AUTOSAR XML (schema 4-2-1)
package /RootP_SR_Data
  sender receiver interface SR_ApportCarbDetecteTest
    data ApportCarbDetecteTest: type=tLOG, init-value=CONST_tLOG_0:0
  sender receiver interface SR_TrebuieSaApara
    data ApportCarbDetecte: type=tLOG, init-value=CONST_tLOG_0:0
package /RootP_ASWC_A26
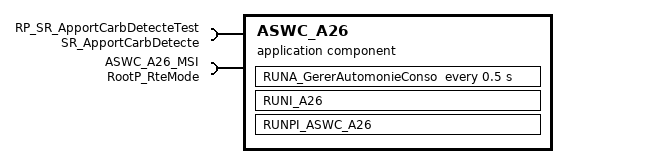
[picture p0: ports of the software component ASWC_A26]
  application sw component type ASWC_A26
    37 x provide/require port:
      PRP_SR_Autonomie: nonqueued-receiver-com-spec{data-element=Autonomie, enable-update=0, handle-data-status=1, handle-never-received=0, init-value=CONST_Autonomie_tWORD_0xFFFF:0xFFFF}, provided-required-interface=SR_Autonomie
      PRP_SR_AutonomieGPL: nonqueued-receiver-com-spec{data-element=AutonomieGPL, enable-update=0, handle-data-status=1, handle-never-received=0, init-value=CONST_AutonomieGPL_tWORD_0x7FF:0x7FF}, provided-required-interface=SR_AutonomieGPL
      PRP_SR_AutonomieInvalide: nonqueued-receiver-com-spec{data-element=AutonomieInvalide, enable-update=0, handle-data-status=1, handle-never-received=0, init-value=CONST_AutonomieInvalide_tLOG_0:0}, provided-required-interface=SR_AutonomieInvalide
      PRP_SR_AutonomieTOTAL: nonqueued-receiver-com-spec{data-element=AutonomieTOTAL, enable-update=0, handle-data-status=1, handle-never-received=0, init-value=CONST_AutonomieTOTAL_tWORD_0x7FF:0x7FF}, provided-required-interface=SR_AutonomieTOTAL
      PRP_SR_ConsoAutonomieGM: nonqueued-receiver-com-spec{data-element=ConsoAutonomieGM, enable-update=0, handle-data-status=1, handle-never-received=0, init-value=CONST_ConsoAutonomieGM_tDWORD_0:0}, provided-required-interface=SR_ConsoAutonomieGM
      PRP_SR_ConsoGPLInvalide: nonqueued-receiver-com-spec{data-element=ConsoGPLInvalide, enable-update=0, handle-data-status=1, handle-never-received=0, init-value=CONST_ConsoGPLInvalide_tLOG_0:0}, provided-required-interface=SR_ConsoGPLInvalide
      PRP_SR_ConsoInst: nonqueued-receiver-com-spec{data-element=ConsoInst, enable-update=0, handle-data-status=1, handle-never-received=0, init-value=CONST_ConsoInst_tWORD_0xFFFF:0xFFFF}, provided-required-interface=SR_ConsoInst
      PRP_SR_ConsoInstGPL: nonqueued-receiver-com-spec{data-element=ConsoInstGPL, enable-update=0, handle-data-status=1, handle-never-received=0, init-value=CONST_ConsoInstGPL_tWORD_0x1FF:0x1FF}, provided-required-interface=SR_ConsoInstGPL
      PRP_SR_ConsoLissee: nonqueued-receiver-com-spec{data-element=ConsoLissee, enable-update=0, handle-data-status=1, handle-never-received=0, init-value=CONST_ConsoLissee_tWORD_0:0}, provided-required-interface=SR_ConsoLissee
      PRP_SR_ConsoMoyenneGPLT1: nonqueued-receiver-com-spec{data-element=ConsoMoyenneGPLT1, enable-update=0, handle-data-status=1, handle-never-received=0, init-value=CONST_ConsoMoyenneGPLT1_tWORD_0:0}, provided-required-interface=SR_ConsoMoyenneGPLT1
      PRP_SR_ConsoMoyenneGPLT2: nonqueued-receiver-com-spec{data-element=ConsoMoyenneGPLT2, enable-update=0, handle-data-status=1, handle-never-received=0, init-value=CONST_ConsoMoyenneGPLT2_tWORD_0:0}, provided-required-interface=SR_ConsoMoyenneGPLT2
      PRP_SR_ConsoMoyenneHY{1..6}: nonqueued-receiver-com-spec{data-element=ConsoMoyenneHY{1..6}, enable-update=0, handle-data-status=1, handle-never-received=0, init-value=CONST_ConsoMoyenneHY{1..6}_tBYTE_0:0}, provided-required-interface=SR_ConsoMoyenneHY{1..6}
      PRP_SR_ConsoMoyenneT1: nonqueued-receiver-com-spec{data-element=ConsoMoyenneT1, enable-update=0, handle-data-status=1, handle-never-received=0, init-value=CONST_ConsoMoyenneT1_tWORD_0:0}, provided-required-interface=SR_ConsoMoyenneT1
      PRP_SR_ConsoMoyenneT2: nonqueued-receiver-com-spec{data-element=ConsoMoyenneT2, enable-update=0, handle-data-status=1, handle-never-received=0, init-value=CONST_ConsoMoyenneT2_tWORD_0:0}, provided-required-interface=SR_ConsoMoyenneT2
      PRP_SR_ConsoReelleInvalide: nonqueued-receiver-com-spec{data-element=ConsoReelleInvalide, enable-update=0, handle-data-status=1, handle-never-received=0, init-value=CONST_ConsoReelleInvalide_tLOG_0:0}, provided-required-interface=SR_ConsoReelleInvalide
      PRP_SR_Conso_WH_Gain{1..6}: nonqueued-receiver-com-spec{data-element=Conso_WH_Gain{1..6}, enable-update=0, handle-data-status=1, handle-never-received=0, init-value=CONST_Conso_WH_Gain{1..6}_tBYTE_0:0}, provided-required-interface=SR_Conso_WH_Gain{1..6}
      PRP_SR_DistAutonomieGM: nonqueued-receiver-com-spec{data-element=DistAutonomieGM, enable-update=0, handle-data-status=1, handle-never-received=0, init-value=CONST_DistAutonomieGM_tDWORD_0:0}, provided-required-interface=SR_DistAutonomieGM
      PRP_SR_NbDemiMedaillesBarre{1..6}: nonqueued-receiver-com-spec{data-element=NbDemiMedaillesBarre{1..6}, enable-update=0, handle-data-status=1, handle-never-received=0, init-value=CONST_NbDemiMedaillesBarre{1..6}_tWORD_0:0}, provided-required-interface=SR_NbDemiMedaillesBarre{1..6}
      PRP_SR_PseudoConsoInvalide: nonqueued-receiver-com-spec{data-element=PseudoConsoInvalide, enable-update=0, handle-data-status=1, handle-never-received=0, init-value=CONST_PseudoConsoInvalide_tLOG_0:0}, provided-required-interface=SR_PseudoConsoInvalide
      PRP_SR_RazOkDeAuCoVersOdo: nonqueued-receiver-com-spec{data-element=RazOkDeAuCoVersOdo, enable-update=0, handle-data-status=1, handle-never-received=0, init-value=CONST_RazOkDeAuCoVersOdo_tLOG_0:0}, provided-required-interface=SR_RazOkDeAuCoVersOdo
      PRP_SR_SAV_ConsoGPLLisse: nonqueued-receiver-com-spec{data-element=SAV_ConsoGPLLisse, enable-update=0, handle-data-status=1, handle-never-received=0, init-value=CONST_SAV_ConsoGPLLisse_tWORD_100:100}, provided-required-interface=SR_SAV_ConsoGPLLisse
      PRP_SR_SAV_ConsoLisse: nonqueued-receiver-com-spec{data-element=SAV_ConsoLisse, enable-update=0, handle-data-status=1, handle-never-received=0, init-value=CONST_SAV_ConsoLisse_tWORD_100:100}, provided-required-interface=SR_SAV_ConsoLisse
    require port RP_SR_ApportCarbDetecteTest: nonqueued-receiver-com-spec{data-element=ApportCarbDetecteTest, enable-update=0, handle-data-status=1, handle-never-received=0, init-value=CONST_ApportCarbDetecte_tLOG_0:0}, required-interface=SR_ApportCarbDetecte
    require port ASWC_A26_MSI: required-interface=RootP_RteMode
    behavior IB_ASWC_A26: data-type-mapping=ApplicationModeMapping, handle-termination-and-restart=NO-SUPPORT
      ar-typed-per-instance-memorys:
        155 x data:
          PA26_ApportCarbDetecte_prec: type=tLOG, init-value=CONST_tLOG_0:0
          PA26_AutonomieCorrigee: type=tWORD, init-value=CONST_tWORD_0:0
          PA26_AutonomieCorrigeeGPL: type=tWORD, init-value=CONST_tWORD_0:0
          PA26_AutonomieHyst: type=tWORD, init-value=CONST_tWORD_0xFFFF:0xFFFF
          PA26_AutonomieHystGPL: type=tWORD, init-value=CONST_tWORD_0xFFFF:0xFFFF
          PA26_AutonomieNonCorrigee: type=tWORD, init-value=CONST_tWORD_0:0
          PA26_AutonomieNonCorrigeeGPL: type=tWORD, init-value=CONST_tWORD_0:0
          PA26_CalculAutonomie: type=tLOG, init-value=CONST_tLOG_0:0
          PA26_CalculAutonomieGPL_GM: type=tLOG, init-value=CONST_tLOG_0:0
          PA26_CalculAutonomieGPL_PSA: type=tLOG, init-value=CONST_tLOG_0:0
          PA26_CalculConso: type=tWORD, init-value=CONST_tWORD_0:0
          PA26_CalculConsoInst: type=tLOG, init-value=CONST_tLOG_0:0
          PA26_CalculConsoInstGPL: type=tLOG, init-value=CONST_tLOG_0:0
          PA26_ConsoCarbReellePrec: type=tBYTE, init-value=CONST_tBYTE_0:0
          PA26_ConsoInst: type=tWORD, init-value=CONST_tWORD_100:100
          PA26_ConsoInstantanee: type=tWORD, init-value=CONST_tWORD_100:100
          PA26_ConsoInstantaneeGPL: type=tWORD, init-value=CONST_tWORD_100:100
          PA26_ConsoInstantGPLPrec: type=tWORD, init-value=CONST_tWORD_100:100
          PA26_ConsoInstantPrec: type=tWORD, init-value=CONST_tWORD_100:100
          PA26_ConsoInstGPL: type=tWORD, init-value=CONST_tWORD_100:100
          PA26_ConsoInstGPLPrec: type=tWORD, init-value=CONST_tWORD_0:0
          PA26_ConsoInstPrec: type=tWORD, init-value=CONST_tWORD_0:0
          PA26_ConsommationGPLPrec: type=tBYTE, init-value=CONST_tBYTE_0:0
          PA26_ConsoMoyenneHY: type=tWORD, init-value=CONST_tWORD_0:0
          PA26_ConsoMoyenneT1GPL: type=tWORD, init-value=CONST_tWORD_0:0
          PA26_ConsoMoyenneT2GPL: type=tWORD, init-value=CONST_tWORD_0:0
          PA26_ConsoMoyenneZoom1Barre{1..6}: type=tBYTE, init-value=CONST_tBYTE_0:0
          PA26_ConsoMoyenneZoom2Barre{1..6}: type=tBYTE, init-value=CONST_tBYTE_0:0
          PA26_ConsoMoyenneZoom3Barre{1..6}: type=tBYTE, init-value=CONST_tBYTE_0:0
          PA26_ConsoMoyenneZoom4Barre{1..6}: type=tBYTE, init-value=CONST_tBYTE_0:0
          PA26_DdeRazOdoPrec: type=tLOG, init-value=CONST_tLOG_0:0
          PA26_DeltaConso: type=tBYTE, init-value=CONST_tBYTE_0:0
          PA26_DeltaConsoGPL: type=tBYTE, init-value=CONST_tBYTE_0:0
          PA26_DeltaConsoReelle: type=tBYTE, init-value=CONST_tBYTE_0:0
          PA26_DeltaDistance: type=tWORD, init-value=CONST_tWORD_0:0
          PA26_DeltaDistanceParcourue: type=tWORD, init-value=CONST_tWORD_0:0
          PA26_DeltaPseudoConsommationCarb: type=tBYTE, init-value=CONST_tBYTE_0:0
          PA26_DistanceParcourue_Prec: type=tWORD, init-value=CONST_tWORD_0:0
          PA26_DistancePreciseT1Prec: type=tDWORD, init-value=CONST_tDWORD_0:0
          PA26_DistancePreciseT2Prec: type=tDWORD, init-value=CONST_tDWORD_0:0
          PA26_DistParcourueHy: type=tDWORD, init-value=CONST_tDWORD_0:0
          PA26_DistParcourueHy_memo: type=tDWORD, init-value=CONST_tDWORD_0:0
          PA26_DistParcourueHy_temp: type=tDWORD, init-value=CONST_tDWORD_0:0
          PA26_DistParcourueZoom1: type=tDWORD, init-value=CONST_tDWORD_0:0
          PA26_DistParcourueZoom1_memo: type=tDWORD, init-value=CONST_tDWORD_0:0
          PA26_DistParcourueZoom1_Prec: type=tDWORD, init-value=CONST_tDWORD_0:0
          PA26_DistParcourueZoom1_temp: type=tDWORD, init-value=CONST_tDWORD_0:0
          PA26_DistParcourueZoom2: type=tDWORD, init-value=CONST_tDWORD_0:0
          PA26_DistParcourueZoom2_memo: type=tDWORD, init-value=CONST_tDWORD_0:0
          PA26_DistParcourueZoom2_Prec: type=tDWORD, init-value=CONST_tDWORD_0:0
          PA26_DistParcourueZoom2_temp: type=tDWORD, init-value=CONST_tDWORD_0:0
          PA26_DistParcourueZoom3: type=tDWORD, init-value=CONST_tDWORD_0:0
          PA26_DistParcourueZoom3_memo: type=tDWORD, init-value=CONST_tDWORD_0:0
          PA26_DistParcourueZoom3_Prec: type=tDWORD, init-value=CONST_tDWORD_0:0
          PA26_DistParcourueZoom3_temp: type=tDWORD, init-value=CONST_tDWORD_0:0
          PA26_DistParcourueZoom4: type=tDWORD, init-value=CONST_tDWORD_0:0
          PA26_DistParcourueZoom4_memo: type=tDWORD, init-value=CONST_tDWORD_0:0
          PA26_DistParcourueZoom4_Prec: type=tDWORD, init-value=CONST_tDWORD_0:0
          PA26_DistParcourueZoom4_temp: type=tDWORD, init-value=CONST_tDWORD_0:0
          PA26_EnergieCalcule: type=tBinaire, init-value=CONST_PA26_EnergieCalcule_tBinaire_cFaux:0
          PA26_EtatConsoMoyenneHY_Valide: type=tBinaire, init-value=CONST_PA26_EtatConsoMoyenneHY_Valide_tBinaire_cVrai:1
          PA26_EtatConsoMoyenneZoom{1..4}_Valide: type=tBinaire, init-value=CONST_PA26_EtatConsoMoyenneZoom{1..4}_Valide_tBinaire_cVrai:1
          PA26_EtatDefautConsoGPL: type=tBYTE, init-value=CONST_tBYTE_15:15
          PA26_EtatDefautConsoReelle: type=tBYTE, init-value=CONST_tBYTE_15:15
          PA26_EtatDefautPseudoConso: type=tBYTE, init-value=CONST_tBYTE_15:15
          PA26_EtatFiltreODBConsoGPLLisse: type=tDWORD, init-value=CONST_tDWORD_0x00032000:0x00032000
          PA26_EtatFiltreODBConsoInst: type=tDWORD, init-value=CONST_tDWORD_1000:1000
          PA26_EtatFiltreODBConsoInstGPL: type=tDWORD, init-value=CONST_tDWORD_1000:1000
          PA26_EtatFiltreODBConsoLisse: type=tDWORD, init-value=CONST_tDWORD_0x00032000:0x00032000
          PA26_EtatFiltreODBMoyenneConso: type=tDWORD, init-value=CONST_tDWORD_0xFFFFFFFF:0xFFFFFFFF
          PA26_EtatFiltreODBMoyenneConsoGPL: type=tDWORD, init-value=CONST_tDWORD_0xFFFFFFFF:0xFFFFFFFF
          PA26_EtatGMPDeHY_Prec: type=t_cEtatHY, init-value=CONST_PA26_EtatGMPDeHY_Prec_t_cEtatHY_cEtatHY_Indetermine:0
          PA26_EtatGMPHy_Valide: type=t_cEtatHY, init-value=CONST_PA26_EtatGMPHy_Valide_t_cEtatHY_cEtatHY_Indetermine:0
          PA26_EtatSurvAcqConso: type=tBILOG, init-value=CONST_tBILOG_0:0
          PA26_FlagAffichageAutonomieInv: type=tLOG, init-value=CONST_tLOG_0:0
          PA26_FlagAffichageAutonomieInvGPL: type=tLOG, init-value=CONST_tLOG_0:0
          PA26_FlagCalculAutonomieInv: type=tLOG, init-value=CONST_tLOG_0:0
          PA26_FlagModeDeFonction: type=tLOG, init-value=CONST_tLOG_0:0
          PA26_Mode_GAZ_Essence: type=tBILOG, init-value=CONST_tBILOG_0:0
          PA26_Mode_GAZ_Essence_Prec: type=tBILOG, init-value=CONST_tBILOG_0:0
          PA26_MoyenneGPLConso: type=tWORD, init-value=CONST_tWORD_100:100
          PA26_NivCarbAffVersCmb: type=tBYTE, init-value=CONST_tBYTE_0:0
          PA26_NivGPLAffichefiltre: type=tBYTE, init-value=CONST_tBYTE_0:0
          PA26_NivGPLAffiche_prec: type=tBYTE, init-value=CONST_tBYTE_0:0
          PA26_OldCstTpsConsoInst: type=tWORD, init-value=CONST_tWORD_10:10
          PA26_OldCstTpsConsoInstGPL: type=tWORD, init-value=CONST_tWORD_10:10
          PA26_OldCstTpsConsoLissee: type=tWORD, init-value=CONST_tWORD_4000:4000
          PA26_PasAffAutonomie: type=tBYTE, init-value=CONST_tBYTE_0:0
          PA26_PasAffAutonomieGPL: type=tBYTE, init-value=CONST_tBYTE_0:0
          PA26_PasAutonomie: type=tBYTE, init-value=CONST_tBYTE_0:0
          PA26_PasAutonomieGPL: type=tBYTE, init-value=CONST_tBYTE_0:0
          PA26_PseudoConsommationCarb_Prec: type=tBYTE, init-value=CONST_tBYTE_0:0
          PA26_QteCarbConsoHy: type=tDWORD, init-value=CONST_tDWORD_0:0
          PA26_QteCarbConsoZoom{1..4}: type=tDWORD, init-value=CONST_tDWORD_0:0
          PA26_QteEnergieRecup: type=tBYTE, init-value=CONST_tBYTE_0:0
          PA26_QteEnergieRecup_memo: type=tBYTE, init-value=CONST_tBYTE_0:0
          PA26_QteEnergieRecup_Prec: type=tBYTE, init-value=CONST_tBYTE_0:0
          PA26_QteEnergieRecup_temp: type=tBYTE, init-value=CONST_tBYTE_0:0
          PA26_SAV_ConsoPreciseT1GPL: type=tDWORD, init-value=CONST_tDWORD_0:0
          PA26_SAV_ConsoPreciseT2GPL: type=tDWORD, init-value=CONST_tDWORD_0:0
          PA26_SAV_DeltaDistancePreciseT1Gaz: type=tDWORD, init-value=CONST_tDWORD_0:0
          PA26_SAV_DeltaDistancePreciseT1GazMem: type=tDWORD, init-value=CONST_tDWORD_0:0
          PA26_SAV_DeltaDistancePreciseT2Gaz: type=tDWORD, init-value=CONST_tDWORD_0:0
          PA26_SAV_DeltaDistancePreciseT2GazMem: type=tDWORD, init-value=CONST_tDWORD_0:0
          PA26_SAV_DistancePreciseT1Prec: type=tDWORD, init-value=CONST_tDWORD_0:0
          PA26_SAV_DistancePreciseT2Prec: type=tDWORD, init-value=CONST_tDWORD_0:0
          PA26_SAV_DistanceT1EssGazMem: type=tDWORD, init-value=CONST_tDWORD_0:0
          PA26_SAV_DistanceT1HorsGaz: type=tDWORD, init-value=CONST_tDWORD_0:0
          PA26_SAV_DistanceT2EssGazMem: type=tDWORD, init-value=CONST_tDWORD_0:0
          PA26_SAV_DistanceT2HorsGaz: type=tDWORD, init-value=CONST_tDWORD_0:0
          PA26_SEC_PremierTelechBSI: type=tLOG, init-value=CONST_tLOG_0:0
          PA26_TempoConfirmDefaut: type=tBYTE, init-value=CONST_tBYTE_0:0
          PA26_TempoDefautConsoGPL: type=tWORD, init-value=CONST_tWORD_0:0
          PA26_TempoDefautConsoReelle: type=tWORD, init-value=CONST_tWORD_0:0
          PA26_TempoDefautPseudoConso: type=tWORD, init-value=CONST_tWORD_0:0
          PA26_TempoGM: type=tBYTE, init-value=CONST_tBYTE_0:0
          PA26_TempoHy: type=tWORD, init-value=CONST_tWORD_0:0
          PA26_TempoMaJ1Seconde: type=tBYTE, init-value=CONST_tBYTE_0:0
          PA26_TempoMaJ1SecondeGPL: type=tBYTE, init-value=CONST_tBYTE_0:0
          PA26_TempoMaJ2Seconde: type=tBYTE, init-value=CONST_tBYTE_0:0
          PA26_TempoMaJ2SecondeGPL: type=tBYTE, init-value=CONST_tBYTE_0:0
          PA26_TempoZoom{1..4}: type=tBYTE, init-value=CONST_tBYTE_0:0
          PA26_Toggle_ConsoLissee: type=tLOG, init-value=CONST_tLOG_0:0
          PA26_Toggle_ConsoLisseeGPL: type=tLOG, init-value=CONST_tLOG_0:0
          PA26_Toggle_ConsoMoyenne: type=tLOG, init-value=CONST_tLOG_0:0
          PA26_Toggle_ConsoMoyenneGPL: type=tLOG, init-value=CONST_tLOG_0:0
      timing event RUNA_GererAutomonieConso_Cyclic: start-on-event=RUNA_GererAutomonieConso, period=0.5
        disabled-mode:
          ASWC_A26_MSI.RteMode.APP_WAKEUP
          ASWC_A26_MSI.RteMode.APP_OFF
          ASWC_A26_MSI.RteMode.APP_SYNC_INIT
          ASWC_A26_MSI.RteMode.APP_CONFIG
      swc mode switch event RUNPI_ASWC_A26_ENTRY: start-on-event=RUNPI_ASWC_A26, activation=ON-ENTRY, mode=ASWC_A26_MSI.RteMode.APP_WAKEUP
      swc mode switch event RUNI_A26_EXIT: start-on-event=RUNI_A26, activation=ON-EXIT, mode=ASWC_A26_MSI.RteMode.APP_WAKEUP
      implicit-inter-runnable-variables:
        5 x data:
          IRVA26_ConsoMoyT1: type=tWORD, init-value=CONST_tWORD_0:0
          IRVA26_ConsoMoyT2: type=tWORD, init-value=CONST_tWORD_0:0
          IRVA26_ConsoPreciseT1: type=tDWORD, init-value=CONST_tDWORD_0:0
          IRVA26_ConsoPreciseT2: type=tDWORD, init-value=CONST_tDWORD_0:0
          IRVA26_MoyenneConso: type=tWORD, init-value=CONST_tWORD_70:70
      runnable RUNA_GererAutomonieConso
        data-read-access:
          162 x access:
            dra_ApportCarbDetecte: accessed-variable=RP_SR_ApportCarbDetecte.ApportCarbDetecte
            dra_CMMMuet_P26: accessed-variable=RP_SR_CMMMuet_P26.CMMMuet_P26
            dra_ConsommationCarbReelle_P26: accessed-variable=RP_SR_ConsommationCarbReelle_P26.ConsommationCarbReelle_P26
            dra_ConsommationGPL: accessed-variable=RP_SR_ConsommationGPL.ConsommationGPL
            dra_DdeRazDeOdometre: accessed-variable=RP_SR_DdeRazDeOdometre.DdeRazDeOdometre
            dra_DdeRazT1_P26: accessed-variable=RP_SR_DdeRazT1_P26.DdeRazT1_P26
            dra_DdeRazT2_P26: accessed-variable=RP_SR_DdeRazT2_P26.DdeRazT2_P26
            dra_DefautJaugeCarbConfirme: accessed-variable=RP_SR_DefautJaugeCarbConfirme.DefautJaugeCarbConfirme
            dra_DistanceParcourue: accessed-variable=RP_SR_DistanceParcourue.DistanceParcourue
            dra_DistanceParcourueFigee: accessed-variable=RP_SR_DistanceParcourueFigee.DistanceParcourueFigee
            dra_DistanceParcourueValide: accessed-variable=RP_SR_DistanceParcourueValide.DistanceParcourueValide
            dra_DistanceT1: accessed-variable=RP_SR_DistanceT1.DistanceT1
            dra_DistanceT2: accessed-variable=RP_SR_DistanceT2.DistanceT2
            dra_DysfVitesseVehicule: accessed-variable=RP_SR_DysfVitesseVehicule.DysfVitesseVehicule
            dra_EtatGMP: accessed-variable=RP_SR_EtatGMP.EtatGMP
            dra_EtatGMPDeHY: accessed-variable=RP_SR_EtatGMPDeHY.EtatGMPDeHY
            dra_EtatModeGaz: accessed-variable=RP_SR_EtatModeGaz.EtatModeGaz
            dra_EtatPrincipalSEV: accessed-variable=RP_SR_EtatPrincipalSEV.EtatPrincipalSEV
            dra_GAZMuet_P26: accessed-variable=RP_SR_GAZMuet_P26.GAZMuet_P26
            dra_GPLModeINFO: accessed-variable=RP_SR_GPLModeINFO.GPLModeINFO
            dra_GPLtankCapacity: accessed-variable=RP_SR_GPLtankCapacity.GPLtankCapacity
            dra_ModeFonctMotGAZ: accessed-variable=RP_SR_ModeFonctMotGAZ.ModeFonctMotGAZ
            dra_NivGPLAffiche: accessed-variable=RP_SR_NivGPLAffiche.NivGPLAffiche
            dra_PhaseVieLS: accessed-variable=RP_SR_PhaseVieLS.PhaseVieLS
            dra_PremiereMesureJC_OK: accessed-variable=RP_SR_PremiereMesureJC_OK.PremiereMesureJC_OK
            dra_PseudoConsommationCarb: accessed-variable=RP_SR_PseudoConsommationCarb.PseudoConsommationCarb
            dra_QteEnergieRecup: accessed-variable=RP_SR_QteEnergieRecup.QteEnergieRecup
            dra_RegimeMoteur_P26: accessed-variable=RP_SR_RegimeMoteur_P26.RegimeMoteur_P26
            dra_SAV_DistancePreciseT1: accessed-variable=RP_SR_SAV_DistancePreciseT1.SAV_DistancePreciseT1
            dra_SAV_DistancePreciseT2: accessed-variable=RP_SR_SAV_DistancePreciseT2.SAV_DistancePreciseT2
            dra_SAV_EtatReseauElectrique: accessed-variable=RP_SR_SAV_EtatReseauElectrique.SAV_EtatReseauElectrique
            dra_SAV_NivCarbAffiche: accessed-variable=RP_SR_SAV_NivCarbAffiche.SAV_NivCarbAffiche
            dra_VitesseVehicule: accessed-variable=RP_SR_VitesseVehicule.VitesseVehicule
            dra_ZoomConsoIHM: accessed-variable=RP_SR_ZoomConsoIHM.ZoomConsoIHM
            dra_C_CONSO_AUTONOMIE_MAX: accessed-variable=RP_SR_C_CONSO_AUTONOMIE_MAX.C_CONSO_AUTONOMIE_MAX
            dra_C_CONSO_BORNE_AUTONOMIE_1: accessed-variable=RP_SR_C_CONSO_BORNE_AUTONOMIE_1.C_CONSO_BORNE_AUTONOMIE_1
            dra_C_CONSO_BORNE_AUTONOMIE_2: accessed-variable=RP_SR_C_CONSO_BORNE_AUTONOMIE_2.C_CONSO_BORNE_AUTONOMIE_2
            dra_C_CONSO_COEF_HYST_MOINS: accessed-variable=RP_SR_C_CONSO_COEF_HYST_MOINS.C_CONSO_COEF_HYST_MOINS
            dra_C_CONSO_COEF_HYST_PLUS: accessed-variable=RP_SR_C_CONSO_COEF_HYST_PLUS.C_CONSO_COEF_HYST_PLUS
            dra_C_CONSO_DISTANCE_MAX: accessed-variable=RP_SR_C_CONSO_DISTANCE_MAX.C_CONSO_DISTANCE_MAX
            dra_C_CONSO_DISTANCE_MINI: accessed-variable=RP_SR_C_CONSO_DISTANCE_MINI.C_CONSO_DISTANCE_MINI
            dra_C_CONSO_HYST_AUTONOMIE_MAX: accessed-variable=RP_SR_C_CONSO_HYST_AUTONOMIE_MAX.C_CONSO_HYST_AUTONOMIE_MAX
            dra_C_CONSO_LIMITE_DETECTION_PIED_LEVE: accessed-variable=RP_SR_C_CONSO_LIMITE_DETECTION_PIED_LEVE.C_CONSO_LIMITE_DETECTION_PIED_LEVE
            dra_C_CONSO_MOTEUR_MIN: accessed-variable=RP_SR_C_CONSO_MOTEUR_MIN.C_CONSO_MOTEUR_MIN
            dra_C_CONSO_PAS_AUTONOMIE_{1..3}: accessed-variable=RP_SR_C_CONSO_PAS_AUTONOMIE_{1..3}.C_CONSO_PAS_AUTONOMIE_{1..3}
            dra_C_CONSO_SECUR_AUTONOMIE: accessed-variable=RP_SR_C_CONSO_SECUR_AUTONOMIE.C_CONSO_SECUR_AUTONOMIE
            dra_C_CONSO_SEUIL_AUTONOMIE: accessed-variable=RP_SR_C_CONSO_SEUIL_AUTONOMIE.C_CONSO_SEUIL_AUTONOMIE
            dra_C_CONSO_SEUIL_AUTONOMIE_INVALIDE: accessed-variable=RP_SR_C_CONSO_SEUIL_AUTONOMIE_INVALIDE.C_CONSO_SEUIL_AUTONOMIE_INVALIDE
            dra_C_CONSO_SEUIL_VIT_FAIBLE_CONSO_LISSEE: accessed-variable=RP_SR_C_CONSO_SEUIL_VIT_FAIBLE_CONSO_LISSEE.C_CONSO_SEUIL_VIT_FAIBLE_CONSO_LISSEE
            dra_C_CONSO_SEUIL_VIT_FIGEAGE_CONSO_INST: accessed-variable=RP_SR_C_CONSO_SEUIL_VIT_FIGEAGE_CONSO_INST.C_CONSO_SEUIL_VIT_FIGEAGE_CONSO_INST
            dra_C_CONSO_SEUIL_VIT_TRES_FAIBLE_CONSO_LISSEE: accessed-variable=RP_SR_C_CONSO_SEUIL_VIT_TRES_FAIBLE_CONSO_LISSEE.C_CONSO_SEUIL_VIT_TRES_FAIBLE_CONSO_LISSEE
            dra_C_CONSO_SEUIL_VITESSE_CONSO_MOY: accessed-variable=RP_SR_C_CONSO_SEUIL_VITESSE_CONSO_MOY.C_CONSO_SEUIL_VITESSE_CONSO_MOY
            dra_C26_AUTONOMIE_MAX: accessed-variable=RP_SR_C26_AUTONOMIE_MAX.C26_AUTONOMIE_MAX
            dra_C26_AUTONOMIE_MAX_GM: accessed-variable=RP_SR_C26_AUTONOMIE_MAX_GM.C26_AUTONOMIE_MAX_GM
            dra_C26_AUTONOMIE_MAX_PSA: accessed-variable=RP_SR_C26_AUTONOMIE_MAX_PSA.C26_AUTONOMIE_MAX_PSA
            dra_C26_BORNE_AUTONOMIE_1: accessed-variable=RP_SR_C26_BORNE_AUTONOMIE_1.C26_BORNE_AUTONOMIE_1
            dra_C26_BORNE_AUTONOMIE_2: accessed-variable=RP_SR_C26_BORNE_AUTONOMIE_2.C26_BORNE_AUTONOMIE_2
            dra_C26_COEF_HYST_MOINS: accessed-variable=RP_SR_C26_COEF_HYST_MOINS.C26_COEF_HYST_MOINS
            dra_C26_COEF_HYST_PLUS: accessed-variable=RP_SR_C26_COEF_HYST_PLUS.C26_COEF_HYST_PLUS
            dra_C26_CONSO_INST_MAX: accessed-variable=RP_SR_C26_CONSO_INST_MAX.C26_CONSO_INST_MAX
            dra_C26_CONSO_MOY_MAX: accessed-variable=RP_SR_C26_CONSO_MOY_MAX.C26_CONSO_MOY_MAX
            dra_C26_DISTANCE_MAX: accessed-variable=RP_SR_C26_DISTANCE_MAX.C26_DISTANCE_MAX
            dra_C26_DISTANCE_MINI: accessed-variable=RP_SR_C26_DISTANCE_MINI.C26_DISTANCE_MINI
            dra_C26_DISTANCE_MINI_HY: accessed-variable=RP_SR_C26_DISTANCE_MINI_HY.C26_DISTANCE_MINI_HY
            dra_C26_FILTER_GM: accessed-variable=RP_SR_C26_FILTER_GM.C26_FILTER_GM
            dra_C26_HYST_AUTONOMIE_MAX: accessed-variable=RP_SR_C26_HYST_AUTONOMIE_MAX.C26_HYST_AUTONOMIE_MAX
            dra_C26_IDLING_TIMEGPL: accessed-variable=RP_SR_C26_IDLING_TIMEGPL.C26_IDLING_TIMEGPL
            dra_C26_LIMITE_DETECTION_PIED_LEVE: accessed-variable=RP_SR_C26_LIMITE_DETECTION_PIED_LEVE.C26_LIMITE_DETECTION_PIED_LEVE
            dra_C26_LIMITE_DETECTION_PIED_LEVE_GPL: accessed-variable=RP_SR_C26_LIMITE_DETECTION_PIED_LEVE_GPL.C26_LIMITE_DETECTION_PIED_LEVE_GPL
            dra_C26_MAXDIST_GM: accessed-variable=RP_SR_C26_MAXDIST_GM.C26_MAXDIST_GM
            dra_C26_MAXFUEL_GM: accessed-variable=RP_SR_C26_MAXFUEL_GM.C26_MAXFUEL_GM
            dra_C26_MOTEUR_MIN: accessed-variable=RP_SR_C26_MOTEUR_MIN.C26_MOTEUR_MIN
            dra_C26_OFFSET_GM: accessed-variable=RP_SR_C26_OFFSET_GM.C26_OFFSET_GM
            dra_C26_PAS_AUTONOMIE_{1..3}: accessed-variable=RP_SR_C26_PAS_AUTONOMIE_{1..3}.C26_PAS_AUTONOMIE_{1..3}
            dra_C26_RANGE_SCALEGPL: accessed-variable=RP_SR_C26_RANGE_SCALEGPL.C26_RANGE_SCALEGPL
            dra_C26_SECUR_AUTONOMIE: accessed-variable=RP_SR_C26_SECUR_AUTONOMIE.C26_SECUR_AUTONOMIE
            dra_C26_SECUR_AUTONOMIE_GPL: accessed-variable=RP_SR_C26_SECUR_AUTONOMIE_GPL.C26_SECUR_AUTONOMIE_GPL
            dra_C26_SEUIL_AUTONOMIE: accessed-variable=RP_SR_C26_SEUIL_AUTONOMIE.C26_SEUIL_AUTONOMIE
            dra_C26_SEUIL_AUTONOMIE_INVALIDE: accessed-variable=RP_SR_C26_SEUIL_AUTONOMIE_INVALIDE.C26_SEUIL_AUTONOMIE_INVALIDE
            dra_C26_SEUIL_VIT_FAIBLE_CONSO_LISSEE: accessed-variable=RP_SR_C26_SEUIL_VIT_FAIBLE_CONSO_LISSEE.C26_SEUIL_VIT_FAIBLE_CONSO_LISSEE
            dra_C26_SEUIL_VIT_FIGEAGE_CONSO_INST: accessed-variable=RP_SR_C26_SEUIL_VIT_FIGEAGE_CONSO_INST.C26_SEUIL_VIT_FIGEAGE_CONSO_INST
            dra_C26_SEUIL_VIT_TRES_FAIBLE_CONSO_LISSEE: accessed-variable=RP_SR_C26_SEUIL_VIT_TRES_FAIBLE_CONSO_LISSEE.C26_SEUIL_VIT_TRES_FAIBLE_CONSO_LISSEE
            dra_C26_SEUIL_VITESSE_CONSO_MOY: accessed-variable=RP_SR_C26_SEUIL_VITESSE_CONSO_MOY.C26_SEUIL_VITESSE_CONSO_MOY
            dra_C26_VAL_MAX_CONSO_MOYENNE_HY: accessed-variable=RP_SR_C26_VAL_MAX_CONSO_MOYENNE_HY.C26_VAL_MAX_CONSO_MOYENNE_HY
            dra_CFG_CAPACITE_RESERVOIR: accessed-variable=RP_SR_CFG_CAPACITE_RESERVOIR.CFG_CAPACITE_RESERVOIR
            dra_CFG_DISPO_PSEUDO_CONSO_CARB: accessed-variable=RP_SR_CFG_DISPO_PSEUDO_CONSO_CARB.CFG_DISPO_PSEUDO_CONSO_CARB
            dra_CFG_PRESENCE_GAZ: accessed-variable=RP_SR_CFG_PRESENCE_GAZ.CFG_PRESENCE_GAZ
            dra_CFG_PRESENCE_ODB: accessed-variable=RP_SR_CFG_PRESENCE_ODB.CFG_PRESENCE_ODB
            dra_CFG_TYPE_CHAINE_TRACTION: accessed-variable=RP_SR_CFG_TYPE_CHAINE_TRACTION.CFG_TYPE_CHAINE_TRACTION
            dra_CFG_TYPE_GPL_IHM: accessed-variable=RP_SR_CFG_TYPE_GPL_IHM.CFG_TYPE_GPL_IHM
            dra_CFG_TYPE_HY: accessed-variable=RP_SR_CFG_TYPE_HY.CFG_TYPE_HY
            dra_CONSO_DELTA_MES_CONSO_CARB: accessed-variable=RP_SR_CONSO_DELTA_MES_CONSO_CARB.CONSO_DELTA_MES_CONSO_CARB
            dra_T_CONSO_FILTR_CONSO_INST_1: accessed-variable=RP_SR_T_CONSO_FILTR_CONSO_INST_1.T_CONSO_FILTR_CONSO_INST_1
            dra_T_CONSO_FILTR_CONSO_INST_2: accessed-variable=RP_SR_T_CONSO_FILTR_CONSO_INST_2.T_CONSO_FILTR_CONSO_INST_2
            dra_T_CONSO_FILTR_CONSO_LISSEE_{1..3}: accessed-variable=RP_SR_T_CONSO_FILTR_CONSO_LISSEE_{1..3}.T_CONSO_FILTR_CONSO_LISSEE_{1..3}
            dra_T_CONSO_FILTR_CONSO_MOY: accessed-variable=RP_SR_T_CONSO_FILTR_CONSO_MOY.T_CONSO_FILTR_CONSO_MOY
            dra_T_CONSO_TEMPO_CONFIRMATION_DEFAUT: accessed-variable=RP_SR_T_CONSO_TEMPO_CONFIRMATION_DEFAUT.T_CONSO_TEMPO_CONFIRMATION_DEFAUT
            dra_T_CONSO_TEMPO_CONSO_INVALIDE: accessed-variable=RP_SR_T_CONSO_TEMPO_CONSO_INVALIDE.T_CONSO_TEMPO_CONSO_INVALIDE
            dra_T26_DELTA_MES_CONSO_CARB: accessed-variable=RP_SR_T26_DELTA_MES_CONSO_CARB.T26_DELTA_MES_CONSO_CARB
            dra_T26_FILTR_CONSO_INST_1: accessed-variable=RP_SR_T26_FILTR_CONSO_INST_1.T26_FILTR_CONSO_INST_1
            dra_T26_FILTR_CONSO_INST_2: accessed-variable=RP_SR_T26_FILTR_CONSO_INST_2.T26_FILTR_CONSO_INST_2
            dra_T26_FILTR_CONSO_INST_GPL_1: accessed-variable=RP_SR_T26_FILTR_CONSO_INST_GPL_1.T26_FILTR_CONSO_INST_GPL_1
            dra_T26_FILTR_CONSO_INST_GPL_2: accessed-variable=RP_SR_T26_FILTR_CONSO_INST_GPL_2.T26_FILTR_CONSO_INST_GPL_2
            dra_T26_FILTR_CONSO_LISSEE_1: accessed-variable=RP_SR_T26_FILTR_CONSO_LISSEE_1.T26_FILTR_CONSO_LISSEE_1
            dra_T26_FILTR_CONSO_LISSEE_1_GPL: accessed-variable=RP_SR_T26_FILTR_CONSO_LISSEE_1_GPL.T26_FILTR_CONSO_LISSEE_1_GPL
            dra_T26_FILTR_CONSO_LISSEE_2: accessed-variable=RP_SR_T26_FILTR_CONSO_LISSEE_2.T26_FILTR_CONSO_LISSEE_2
            dra_T26_FILTR_CONSO_LISSEE_2_GPL: accessed-variable=RP_SR_T26_FILTR_CONSO_LISSEE_2_GPL.T26_FILTR_CONSO_LISSEE_2_GPL
            dra_T26_FILTR_CONSO_LISSEE_3: accessed-variable=RP_SR_T26_FILTR_CONSO_LISSEE_3.T26_FILTR_CONSO_LISSEE_3
            dra_T26_FILTR_CONSO_LISSEE_3_GPL: accessed-variable=RP_SR_T26_FILTR_CONSO_LISSEE_3_GPL.T26_FILTR_CONSO_LISSEE_3_GPL
            dra_T26_FILTR_CONSO_MOY: accessed-variable=RP_SR_T26_FILTR_CONSO_MOY.T26_FILTR_CONSO_MOY
            dra_T26_FILTR_CONSO_MOY_GPL: accessed-variable=RP_SR_T26_FILTR_CONSO_MOY_GPL.T26_FILTR_CONSO_MOY_GPL
            dra_T26_TEMPO_CONFIRMATION_DEFAUT: accessed-variable=RP_SR_T26_TEMPO_CONFIRMATION_DEFAUT.T26_TEMPO_CONFIRMATION_DEFAUT
            dra_T26_TEMPO_CONSO_INVALIDE: accessed-variable=RP_SR_T26_TEMPO_CONSO_INVALIDE.T26_TEMPO_CONSO_INVALIDE
            dra_T26_TEMPO_HISTO_HY: accessed-variable=RP_SR_T26_TEMPO_HISTO_HY.T26_TEMPO_HISTO_HY
            dra_T26_TEMPO_HISTO_ZOOM{1..4}: accessed-variable=RP_SR_T26_TEMPO_HISTO_ZOOM{1..4}.T26_TEMPO_HISTO_ZOOM{1..4}
            dra_VAL_MEDAILLE: accessed-variable=RP_SR_VAL_MEDAILLE.VAL_MEDAILLE
            dra_Autonomie: accessed-variable=PRP_SR_Autonomie.Autonomie
            dra_AutonomieGPL: accessed-variable=PRP_SR_AutonomieGPL.AutonomieGPL
            dra_AutonomieInvalide: accessed-variable=PRP_SR_AutonomieInvalide.AutonomieInvalide
            dra_AutonomieTOTAL: accessed-variable=PRP_SR_AutonomieTOTAL.AutonomieTOTAL
            dra_ConsoAutonomieGM: accessed-variable=PRP_SR_ConsoAutonomieGM.ConsoAutonomieGM
            dra_ConsoGPLInvalide: accessed-variable=PRP_SR_ConsoGPLInvalide.ConsoGPLInvalide
            dra_ConsoInst: accessed-variable=PRP_SR_ConsoInst.ConsoInst
            dra_ConsoInstGPL: accessed-variable=PRP_SR_ConsoInstGPL.ConsoInstGPL
            dra_ConsoLissee: accessed-variable=PRP_SR_ConsoLissee.ConsoLissee
            dra_ConsoMoyenneGPLT1: accessed-variable=PRP_SR_ConsoMoyenneGPLT1.ConsoMoyenneGPLT1
            dra_ConsoMoyenneGPLT2: accessed-variable=PRP_SR_ConsoMoyenneGPLT2.ConsoMoyenneGPLT2
            dra_ConsoMoyenneHY{1..6}: accessed-variable=PRP_SR_ConsoMoyenneHY{1..6}.ConsoMoyenneHY{1..6}
            dra_ConsoMoyenneT1: accessed-variable=PRP_SR_ConsoMoyenneT1.ConsoMoyenneT1
            dra_ConsoMoyenneT2: accessed-variable=PRP_SR_ConsoMoyenneT2.ConsoMoyenneT2
            dra_ConsoReelleInvalide: accessed-variable=PRP_SR_ConsoReelleInvalide.ConsoReelleInvalide
            dra_Conso_WH_Gain{1..6}: accessed-variable=PRP_SR_Conso_WH_Gain{1..6}.Conso_WH_Gain{1..6}
            dra_DistAutonomieGM: accessed-variable=PRP_SR_DistAutonomieGM.DistAutonomieGM
            dra_NbDemiMedaillesBarre{1..6}: accessed-variable=PRP_SR_NbDemiMedaillesBarre{1..6}.NbDemiMedaillesBarre{1..6}
            dra_PseudoConsoInvalide: accessed-variable=PRP_SR_PseudoConsoInvalide.PseudoConsoInvalide
            dra_RazOkDeAuCoVersOdo: accessed-variable=PRP_SR_RazOkDeAuCoVersOdo.RazOkDeAuCoVersOdo
            dra_SAV_ConsoGPLLisse: accessed-variable=PRP_SR_SAV_ConsoGPLLisse.SAV_ConsoGPLLisse
            dra_SAV_ConsoLisse: accessed-variable=PRP_SR_SAV_ConsoLisse.SAV_ConsoLisse
        data-write-access:
          37 x access:
            dwa_Autonomie: accessed-variable=PRP_SR_Autonomie.Autonomie
            dwa_AutonomieGPL: accessed-variable=PRP_SR_AutonomieGPL.AutonomieGPL
            dwa_AutonomieInvalide: accessed-variable=PRP_SR_AutonomieInvalide.AutonomieInvalide
            dwa_AutonomieTOTAL: accessed-variable=PRP_SR_AutonomieTOTAL.AutonomieTOTAL
            dwa_ConsoAutonomieGM: accessed-variable=PRP_SR_ConsoAutonomieGM.ConsoAutonomieGM
            dwa_ConsoGPLInvalide: accessed-variable=PRP_SR_ConsoGPLInvalide.ConsoGPLInvalide
            dwa_ConsoInst: accessed-variable=PRP_SR_ConsoInst.ConsoInst
            dwa_ConsoInstGPL: accessed-variable=PRP_SR_ConsoInstGPL.ConsoInstGPL
            dwa_ConsoLissee: accessed-variable=PRP_SR_ConsoLissee.ConsoLissee
            dwa_ConsoMoyenneGPLT1: accessed-variable=PRP_SR_ConsoMoyenneGPLT1.ConsoMoyenneGPLT1
            dwa_ConsoMoyenneGPLT2: accessed-variable=PRP_SR_ConsoMoyenneGPLT2.ConsoMoyenneGPLT2
            dwa_ConsoMoyenneHY{1..6}: accessed-variable=PRP_SR_ConsoMoyenneHY{1..6}.ConsoMoyenneHY{1..6}
            dwa_ConsoMoyenneT1: accessed-variable=PRP_SR_ConsoMoyenneT1.ConsoMoyenneT1
            dwa_ConsoMoyenneT2: accessed-variable=PRP_SR_ConsoMoyenneT2.ConsoMoyenneT2
            dwa_ConsoReelleInvalide: accessed-variable=PRP_SR_ConsoReelleInvalide.ConsoReelleInvalide
            dwa_Conso_WH_Gain{1..6}: accessed-variable=PRP_SR_Conso_WH_Gain{1..6}.Conso_WH_Gain{1..6}
            dwa_DistAutonomieGM: accessed-variable=PRP_SR_DistAutonomieGM.DistAutonomieGM
            dwa_NbDemiMedaillesBarre{1..6}: accessed-variable=PRP_SR_NbDemiMedaillesBarre{1..6}.NbDemiMedaillesBarre{1..6}
            dwa_PseudoConsoInvalide: accessed-variable=PRP_SR_PseudoConsoInvalide.PseudoConsoInvalide
            dwa_RazOkDeAuCoVersOdo: accessed-variable=PRP_SR_RazOkDeAuCoVersOdo.RazOkDeAuCoVersOdo
            dwa_SAV_ConsoGPLLisse: accessed-variable=PRP_SR_SAV_ConsoGPLLisse.SAV_ConsoGPLLisse
            dwa_SAV_ConsoLisse: accessed-variable=PRP_SR_SAV_ConsoLisse.SAV_ConsoLisse
        read-local-variables:
          5 x access:
            rlv_IRVA26_ConsoMoyT1: accessed-variable=IRVA26_ConsoMoyT1
            rlv_IRVA26_ConsoMoyT2: accessed-variable=IRVA26_ConsoMoyT2
            rlv_IRVA26_ConsoPreciseT1: accessed-variable=IRVA26_ConsoPreciseT1
            rlv_IRVA26_ConsoPreciseT2: accessed-variable=IRVA26_ConsoPreciseT2
            rlv_IRVA26_MoyenneConso: accessed-variable=IRVA26_MoyenneConso
        written-local-variables:
          5 x access:
            wlv_IRVA26_ConsoMoyT1: accessed-variable=IRVA26_ConsoMoyT1
            wlv_IRVA26_ConsoMoyT2: accessed-variable=IRVA26_ConsoMoyT2
            wlv_IRVA26_ConsoPreciseT1: accessed-variable=IRVA26_ConsoPreciseT1
            wlv_IRVA26_ConsoPreciseT2: accessed-variable=IRVA26_ConsoPreciseT2
            wlv_IRVA26_MoyenneConso: accessed-variable=IRVA26_MoyenneConso
      runnable RUNI_A26
        data-read-access:
          15 x access:
            dra_SAV_DistancePreciseT1: accessed-variable=RP_SR_SAV_DistancePreciseT1.SAV_DistancePreciseT1
            dra_SAV_DistancePreciseT2: accessed-variable=RP_SR_SAV_DistancePreciseT2.SAV_DistancePreciseT2
            dra_C26_ALT_FR_DISTANCE_SEED: accessed-variable=RP_SR_C26_ALT_FR_DISTANCE_SEED.C26_ALT_FR_DISTANCE_SEED
            dra_C26_ALT_FR_FUEL_USED_SEED: accessed-variable=RP_SR_C26_ALT_FR_FUEL_USED_SEED.C26_ALT_FR_FUEL_USED_SEED
            dra_AutonomieInvalide: accessed-variable=PRP_SR_AutonomieInvalide.AutonomieInvalide
            dra_ConsoAutonomieGM: accessed-variable=PRP_SR_ConsoAutonomieGM.ConsoAutonomieGM
            dra_ConsoMoyenneHY{1..6}: accessed-variable=PRP_SR_ConsoMoyenneHY{1..6}.ConsoMoyenneHY{1..6}
            dra_ConsoMoyenneT1: accessed-variable=PRP_SR_ConsoMoyenneT1.ConsoMoyenneT1
            dra_ConsoMoyenneT2: accessed-variable=PRP_SR_ConsoMoyenneT2.ConsoMoyenneT2
            dra_DistAutonomieGM: accessed-variable=PRP_SR_DistAutonomieGM.DistAutonomieGM
        data-write-access:
          11 x access:
            dwa_AutonomieInvalide: accessed-variable=PRP_SR_AutonomieInvalide.AutonomieInvalide
            dwa_ConsoAutonomieGM: accessed-variable=PRP_SR_ConsoAutonomieGM.ConsoAutonomieGM
            dwa_ConsoMoyenneHY{1..6}: accessed-variable=PRP_SR_ConsoMoyenneHY{1..6}.ConsoMoyenneHY{1..6}
            dwa_ConsoMoyenneT1: accessed-variable=PRP_SR_ConsoMoyenneT1.ConsoMoyenneT1
            dwa_ConsoMoyenneT2: accessed-variable=PRP_SR_ConsoMoyenneT2.ConsoMoyenneT2
            dwa_DistAutonomieGM: accessed-variable=PRP_SR_DistAutonomieGM.DistAutonomieGM
        read-local-variables:
          5 x access:
            rlv_IRVA26_ConsoMoyT1: accessed-variable=IRVA26_ConsoMoyT1
            rlv_IRVA26_ConsoMoyT2: accessed-variable=IRVA26_ConsoMoyT2
            rlv_IRVA26_ConsoPreciseT1: accessed-variable=IRVA26_ConsoPreciseT1
            rlv_IRVA26_ConsoPreciseT2: accessed-variable=IRVA26_ConsoPreciseT2
            rlv_IRVA26_MoyenneConso: accessed-variable=IRVA26_MoyenneConso
      runnable RUNPI_ASWC_A26
package /RootP_Implementatation
  swc implementation Implementatation_ASWC_A26: programming-language=C, sw-version=1.0.0, vendor-id=1, behavior=IB_ASWC_A26
    code-descriptors:
      code SRC: artifact-descriptors=autosar-engineering-object={short-label=EngObject, category=SWSRC}
    resource consumption Resources
